# STM32H7A3x register map
File version: 2.0
CPU: CM7 r0p1, little endian, MPU, FPU, 4 interrupt priority bits
Registers are 32-bit, read-write, reset 0x0 unless marked. A register's access mark holds for its fields unless they carry their own. Offsets are from the block's base; [hi:lo] are bit positions; {n}, {i} and the like mark numbered series.

## STK — SysTick timer
Base 0xE000E010
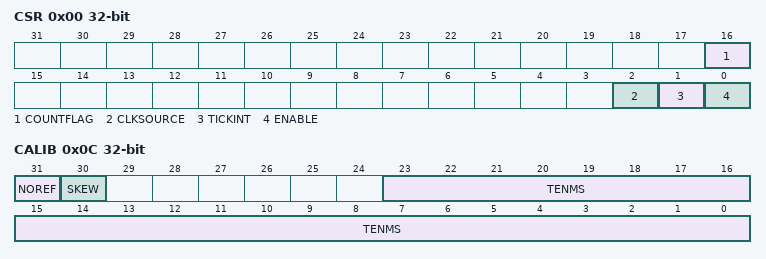
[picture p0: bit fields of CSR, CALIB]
0x00 CSR — SysTick control and status register
  [16] COUNTFLAG
  [2] CLKSOURCE — Clock source selection
  [1] TICKINT — SysTick exception request enable
  [0] ENABLE — Counter enable
0x04 RVR — SysTick reload value register
  [23:0] RELOAD — RELOAD value
0x08 CVR — SysTick current value register
  [23:0] CURRENT — Current counter value
0x0C CALIB — SysTick calibration value register
  [31] NOREF — NOREF flag. Reads as zero
  [30] SKEW — SKEW flag: Indicates whether the TENMS value is exact
  [23:0] TENMS — Calibration value

## SWPMI — Single Wire Protocol Master Interface
Base 0x40008800
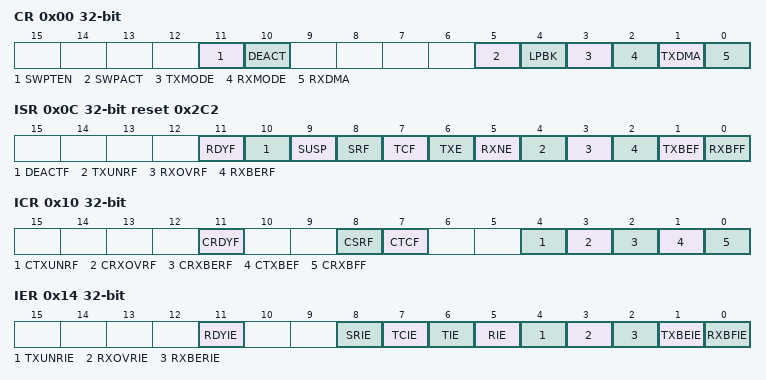
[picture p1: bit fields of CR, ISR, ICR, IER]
0x00 CR — SWPMI Configuration/Control register
  [11] SWPTEN — Single wire protocol master transceiver enable
  [10] DEACT — Single wire protocol master interface deactivate
  [5] SWPACT — Single wire protocol master interface activate
  [4] LPBK — Loopback mode enable
  [3] TXMODE — Transmission buffering mode
  [2] RXMODE — Reception buffering mode
  [1] TXDMA — Transmission DMA enable
  [0] RXDMA — Reception DMA enable
0x04 BRR reset 0x1 — SWPMI Bitrate register
  [7:0] BR — Bitrate prescaler
0x0C ISR ro reset 0x2C2 — SWPMI Interrupt and Status register
  [11] RDYF — transceiver ready flag
  [10] DEACTF — DEACTIVATED flag
  [9] SUSP — SUSPEND flag
  [8] SRF — Slave resume flag
  [7] TCF — Transfer complete flag
  [6] TXE — Transmit data register empty
  [5] RXNE — Receive data register not empty
  [4] TXUNRF — Transmit underrun error flag
  [3] RXOVRF — Receive overrun error flag
  [2] RXBERF — Receive CRC error flag
  [1] TXBEF — Transmit buffer empty flag
  [0] RXBFF — Receive buffer full flag
0x10 ICR wo — SWPMI Interrupt Flag Clear register
  [11] CRDYF — Clear transceiver ready flag
  [8] CSRF — Clear slave resume flag
  [7] CTCF — Clear transfer complete flag
  [4] CTXUNRF — Clear transmit underrun error flag
  [3] CRXOVRF — Clear receive overrun error flag
  [2] CRXBERF — Clear receive CRC error flag
  [1] CTXBEF — Clear transmit buffer empty flag
  [0] CRXBFF — Clear receive buffer full flag
0x14 IER — SWPMI Interrupt Enable register
  [11] RDYIE — Transceiver ready interrupt enable
  [8] SRIE — Slave resume interrupt enable
  [7] TCIE — Transmit complete interrupt enable
  [6] TIE — Transmit interrupt enable
  [5] RIE — Receive interrupt enable
  [4] TXUNRIE — Transmit underrun error interrupt enable
  [3] RXOVRIE — Receive overrun error interrupt enable
  [2] RXBERIE — Receive CRC error interrupt enable
  [1] TXBEIE — Transmit buffer empty interrupt enable
  [0] RXBFIE — Receive buffer full interrupt enable
0x18 RFL ro — SWPMI Receive Frame Length register
  [4:0] RFL — Receive frame length
0x1C TDR wo — SWPMI Transmit data register
  [31:0] TD — Transmit data
0x20 RDR ro — SWPMI Receive data register
  [31:0] RD — received data
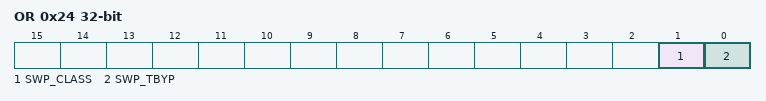
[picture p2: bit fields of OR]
0x24 OR — SWPMI Option register
  [1] SWP_CLASS — SWP class selection
  [0] SWP_TBYP — SWP transceiver bypass

## SYSCFG — System configuration controller
Base 0x58000400
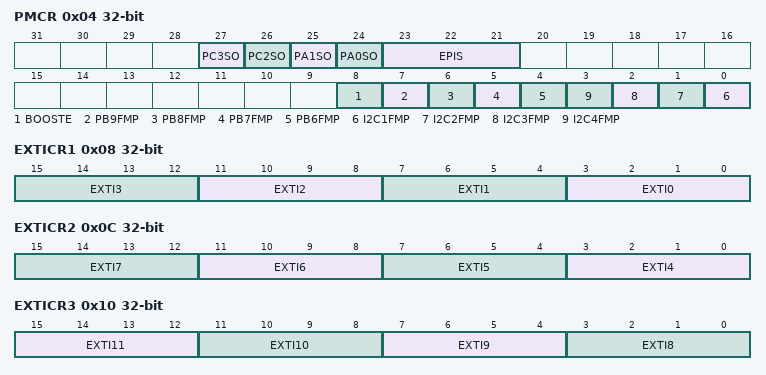
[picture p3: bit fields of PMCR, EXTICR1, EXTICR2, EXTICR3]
0x04 PMCR — peripheral mode configuration register
  [27] PC3SO — PC3 Switch Open
  [26] PC2SO — PC2 Switch Open
  [25] PA1SO — PA1 Switch Open
  [24] PA0SO — PA0 Switch Open
  [23:21] EPIS — Ethernet PHY Interface Selection
  [8] BOOSTE — Booster Enable
  [7] PB9FMP — PB(9) Fm+
  [6] PB8FMP — PB(8) Fast Mode Plus
  [5] PB7FMP — PB(7) Fast Mode Plus
  [4] PB6FMP — PB(6) Fm+
  [n-1] I2C{n}FMP (n=1..4) — I2C{n} Fm+
0x08 EXTICR1 — external interrupt configuration register 1
  [4n+3:4n] EXTI{n} (n=0..3) — EXTI x configuration (x = 0 to 3)
0x0C EXTICR2 — external interrupt configuration register 2
  [4n-13:4n-16] EXTI{n} (n=4..7) — EXTI x configuration (x = 4 to 7)
0x10 EXTICR3 — external interrupt configuration register 3
  [15:12] EXTI11 — EXTI x configuration (x = 8 to 11)
  [11:8] EXTI10
  [7:4] EXTI9 — EXTI x configuration (x = 8 to 11)
  [3:0] EXTI8 — EXTI x configuration (x = 8 to 11)
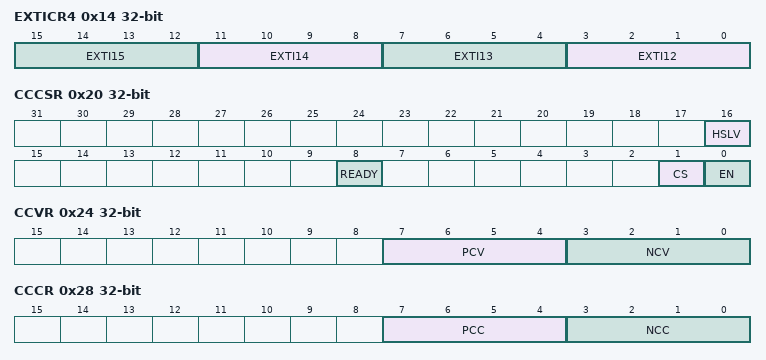
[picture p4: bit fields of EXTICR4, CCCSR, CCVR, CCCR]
0x14 EXTICR4 — external interrupt configuration register 4
  [4n-45:4n-48] EXTI{n} (n=12..15) — EXTI x configuration (x = 12 to 15)
0x20 CCCSR — compensation cell control/status register
  [16] HSLV — High-speed at low-voltage
  [8] READY — Compensation cell ready flag
  [1] CS — Code selection
  [0] EN — enable
0x24 CCVR ro — SYSCFG compensation cell value register
  [7:4] PCV — PMOS compensation value
  [3:0] NCV — NMOS compensation value
0x28 CCCR — SYSCFG compensation cell code register
  [7:4] PCC — PMOS compensation code
  [3:0] NCC — NMOS compensation code
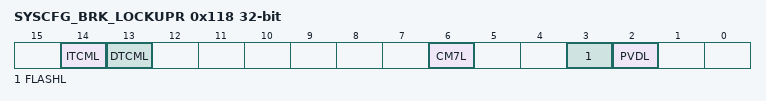
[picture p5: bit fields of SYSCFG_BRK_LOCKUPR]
0x118 SYSCFG_BRK_LOCKUPR — SYSCFG timer break lockup register
  [14] ITCML — ITCM double ECC error signal lock
  [13] DTCML — D1TCM or D0TCM double ECC error signal lock
  [6] CM7L — CortexÃƒÆ’Ã¢â‚¬Å¡Ãƒâ€šÃ‚Â®-M7 LOCKUP (HardFault) output enable bit
  [3] FLASHL — Flash double ECC error lock bit
  [2] PVDL — PVD lock enable bit.
